AUTOSAR XML (schema 4-3-0)
package /ComponentTypes
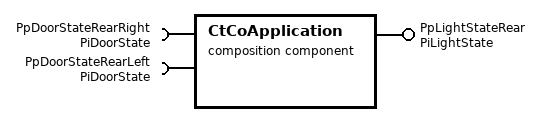
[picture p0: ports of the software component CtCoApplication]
  composition sw component type CtCoApplication
    provide port PpLightStateRear: nonqueued-sender-com-spec{data-element=DeLightState, init-value=0}, provided-interface=PiLightState
    require port PpDoorStateRearRight: nonqueued-receiver-com-spec{data-element=DeDoorState, filter=data-filter-type=ALWAYS, init-value=0}, required-interface=PiDoorState
    require port PpDoorStateRearLeft: nonqueued-receiver-com-spec{data-element=DeDoorState, filter=data-filter-type=ALWAYS, init-value=0}, required-interface=PiDoorState
    6 x component:
      CpSaDoorFrontLeft: type=CtSaDoor
      CpSaInteriorLightFront: type=CtSaInteriorLight
      CpApMySwc: type=CtApMySwc
      CpSaDoorFrontRight: type=CtSaDoor
      CpCddIoHwAb: type=CtCddIoHwAb
      CpSaDisplay: type=CtSaDisplay
    connect CpApMySwc.PpLightStateFront -> CpSaInteriorLightFront.PpLightState
    connect CpSaDoorFrontLeft.PpDoorState -> CpApMySwc.PpDoorStateFrontLeft
    connect CpSaDoorFrontRight.PpDoorState -> CpApMySwc.PpDoorStateFrontRight
    connect CpCddIoHwAb.PpInteriorLightFront -> CpSaInteriorLightFront.PpInteriorLightIoHwAb
    connect CpCddIoHwAb.PpDoorFrontLeft -> CpSaDoorFrontLeft.PpDoorIoHwAb
    connect CpCddIoHwAb.PpDoorFrontRight -> CpSaDoorFrontRight.PpDoorIoHwAb
    connect CpCddIoHwAb.PpInteriorLightFrontDEFECT -> CpSaInteriorLightFront.PpInteriorLightDefect
    delegate CpApMySwc.PpLightStateRear <-> outer port PpLightStateRear
    delegate CpApMySwc.PpDoorStateRearRight <-> outer port PpDoorStateRearRight
    delegate CpApMySwc.PpDoorStateRearLeft <-> outer port PpDoorStateRearLeft
    connect CpApMySwc.PpDisplayState -> CpSaDisplay.PpDisplayState
    connect CpSaDisplay.PpLocalIgnitionState -> CpApMySwc.PpLocalIgnitionState
    connect CpCddIoHwAb.PpDisplayState -> CpSaDisplay.PpDisplayStateIoHwAb
    connect CpCddIoHwAb.PpLocalClamp15 -> CpSaDisplay.PplocalIgnitionStateIoHwAb
